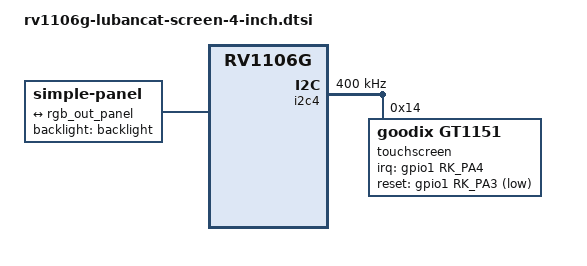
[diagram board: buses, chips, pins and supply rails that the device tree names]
// SPDX-License-Identifier: (GPL-2.0+ OR MIT)
/*
 * Copyright (c) 2023 Rockchip Electronics Co., Ltd.
 */

#include <dt-bindings/input/input.h>
#include <dt-bindings/display/media-bus-format.h>

/ {
	panel: panel {
		compatible = "simple-panel";
		status = "okay";
		backlight = <&backlight>;
		bus-format = <MEDIA_BUS_FMT_RGB666_1X18>;
        // enable-gpios = <&gpio0 RK_PA6 GPIO_ACTIVE_HIGH>;
        // enable-delay-ms = <20>;

		display-timings {
			native-mode = <&timing0>;

			timing0: timing0 {
				clock-frequency = <20000000>;
				hactive = <480>;
				vactive = <272>;
				hback-porch = <43>;
				hfront-porch = <8>;
				vback-porch = <12>;
				vfront-porch = <8>;
				hsync-len = <4>;
				vsync-len = <4>; //value range <2~22>
				hsync-active = <0>;
				vsync-active = <0>;
				de-active = <0>;
				pixelclk-active = <0>;
			};
		};

		port {
			panel_in_rgb: endpoint {
				remote-endpoint = <&rgb_out_panel>;
			};
		};
	};
};

&i2c4 {
    status = "okay";
    clock-frequency = <400000>;
    pinctrl-names = "default";
    pinctrl-0 = <&i2c4m2_xfer>;

	touchscreen@14 {
		compatible = "goodix,gt1151";
		reg = <0x14>;
		interrupt-parent = <&gpio1>;
		interrupts = <RK_PA4 IRQ_TYPE_LEVEL_LOW>;
		irq-gpios = <&gpio1 RK_PA4 GPIO_ACTIVE_HIGH>;
		reset-gpios = <&gpio1 RK_PA3 GPIO_ACTIVE_LOW>;
	};
};

